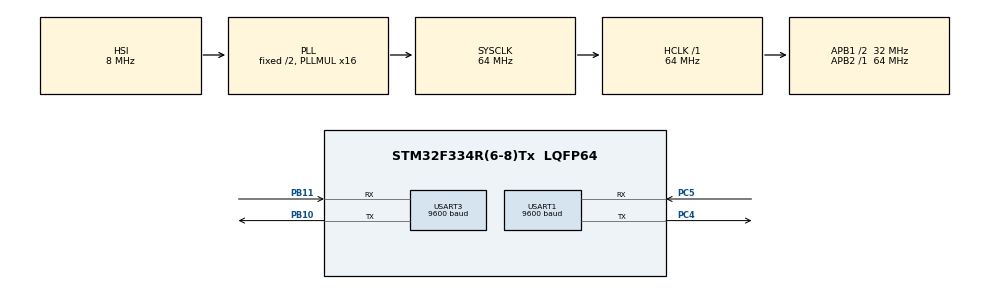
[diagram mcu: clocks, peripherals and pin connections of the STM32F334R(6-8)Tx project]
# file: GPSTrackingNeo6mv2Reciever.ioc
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Mcu.Family=STM32F3
Mcu.Name=STM32F334R(6-8)Tx
Mcu.Package=LQFP64
NVIC.PriorityGroup=NVIC_PRIORITYGROUP_0
NVIC.USART1_IRQn=true\:0\:0\:false\:false\:true\:true\:true\:true
NVIC.USART3_IRQn=true\:0\:0\:false\:false\:true\:true\:true\:true
PA13.Mode=Serial_Wire
PA13.Signal=SYS_JTMS-SWDIO
PA14.Mode=Serial_Wire
PA14.Signal=SYS_JTCK-SWCLK
PB10.Mode=Asynchronous
PB10.Signal=USART3_TX
PB11.Mode=Asynchronous
PB11.Signal=USART3_RX
PC4.Mode=Asynchronous
PC4.Signal=USART1_TX
PC5.Mode=Asynchronous
PC5.Signal=USART1_RX
ProjectManager.HeapSize=0x200
ProjectManager.StackSize=0x400
ProjectManager.TargetToolchain=STM32CubeIDE
RCC.AHBFreq_Value=64000000
RCC.APB1CLKDivider=RCC_HCLK_DIV2
RCC.APB1Freq_Value=32000000
RCC.APB1TimFreq_Value=64000000
RCC.APB2Freq_Value=64000000
RCC.APB2TimFreq_Value=64000000
RCC.CortexFreq_Value=64000000
RCC.FLatency-AdvancedSettings=FLASH_LATENCY_2
RCC.HCLKFreq_Value=64000000
RCC.HSE_VALUE=8000000
RCC.HSI_VALUE=8000000
RCC.PLLMUL=RCC_PLL_MUL16
RCC.SYSCLKFreq_VALUE=64000000
RCC.SYSCLKSourceVirtual=RCC_SYSCLKSOURCE_PLLCLK
USART1.BaudRate=9600
USART1.VirtualMode-Asynchronous=VM_ASYNC
USART3.BaudRate=9600
USART3.VirtualMode-Asynchronous=VM_ASYNC
board=NUCLEO-F334R8

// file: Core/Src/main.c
/* USER CODE BEGIN Header */
/**
  ******************************************************************************
  * @file           : main.c
  * @brief          : Main program body
  ******************************************************************************
  * @attention
  *
  * Copyright (c) 2023 STMicroelectronics.
  * All rights reserved.
  *
  * This software is licensed under terms that can be found in the LICENSE file
  * in the root directory of this software component.
  * If no LICENSE file comes with this software, it is provided AS-IS.
  *
  ******************************************************************************
  */
/* USER CODE END Header */
#include "main.h"

UART_HandleTypeDef huart1;
UART_HandleTypeDef huart3;

/* USER CODE BEGIN PV */

char RxBuffer[24] = { 0 };
char Rxcuffer[1];
int cnt=0;

/* USER CODE END PV */

void SystemClock_Config(void);
static void MX_GPIO_Init(void);
static void MX_USART3_UART_Init(void);
static void MX_USART1_UART_Init(void);

/* USER CODE BEGIN 0 */
void HAL_UART_RxCpltCallback(UART_HandleTypeDef *huart) {

	if (huart->Instance == USART1) {
		//if (Counter_Dma == 0) {
		RxBuffer[cnt++] = Rxcuffer[0];
		if(cnt>23){

			HAL_UART_Transmit(&huart3, RxBuffer,sizeof(RxBuffer), HAL_MAX_DELAY);
			cnt=0;
		}

	}

	HAL_UART_Receive_IT(&huart3, Rxcuffer, 1);

}
/* USER CODE END 0 */

int main(void)
{

  /* MCU Configuration--------------------------------------------------------*/

  /* Reset of all peripherals, Initializes the Flash interface and the Systick. */
  HAL_Init();

  /* Configure the system clock */
  SystemClock_Config();

  /* Initialize all configured peripherals */
  MX_GPIO_Init();
  MX_USART3_UART_Init();
  MX_USART1_UART_Init();

  /* Infinite loop */
  while (1)
  {

  }
}

void SystemClock_Config(void)
{
  RCC_OscInitTypeDef RCC_OscInitStruct = {0};
  RCC_ClkInitTypeDef RCC_ClkInitStruct = {0};
  RCC_PeriphCLKInitTypeDef PeriphClkInit = {0};

  /** Initializes the RCC Oscillators according to the specified parameters
  * in the RCC_OscInitTypeDef structure.
  */
  RCC_OscInitStruct.OscillatorType = RCC_OSCILLATORTYPE_HSI;
  RCC_OscInitStruct.HSIState = RCC_HSI_ON;
  RCC_OscInitStruct.HSICalibrationValue = RCC_HSICALIBRATION_DEFAULT;
  RCC_OscInitStruct.PLL.PLLState = RCC_PLL_ON;
  RCC_OscInitStruct.PLL.PLLSource = RCC_PLLSOURCE_HSI;
  RCC_OscInitStruct.PLL.PLLMUL = RCC_PLL_MUL16;
  if (HAL_RCC_OscConfig(&RCC_OscInitStruct) != HAL_OK)
  {
    Error_Handler();
  }

  /** Initializes the CPU, AHB and APB buses clocks
  */
  RCC_ClkInitStruct.ClockType = RCC_CLOCKTYPE_HCLK|RCC_CLOCKTYPE_SYSCLK
                              |RCC_CLOCKTYPE_PCLK1|RCC_CLOCKTYPE_PCLK2;
  RCC_ClkInitStruct.SYSCLKSource = RCC_SYSCLKSOURCE_PLLCLK;
  RCC_ClkInitStruct.AHBCLKDivider = RCC_SYSCLK_DIV1;
  RCC_ClkInitStruct.APB1CLKDivider = RCC_HCLK_DIV2;
  RCC_ClkInitStruct.APB2CLKDivider = RCC_HCLK_DIV1;

  if (HAL_RCC_ClockConfig(&RCC_ClkInitStruct, FLASH_LATENCY_2) != HAL_OK)
  {
    Error_Handler();
  }
  PeriphClkInit.PeriphClockSelection = RCC_PERIPHCLK_USART1;
  PeriphClkInit.Usart1ClockSelection = RCC_USART1CLKSOURCE_PCLK1;
  if (HAL_RCCEx_PeriphCLKConfig(&PeriphClkInit) != HAL_OK)
  {
    Error_Handler();
  }
}

static void MX_USART1_UART_Init(void)
{

  huart1.Instance = USART1;
  huart1.Init.BaudRate = 9600;
  huart1.Init.WordLength = UART_WORDLENGTH_8B;
  huart1.Init.StopBits = UART_STOPBITS_1;
  huart1.Init.Parity = UART_PARITY_NONE;
  huart1.Init.Mode = UART_MODE_TX_RX;
  huart1.Init.HwFlowCtl = UART_HWCONTROL_NONE;
  huart1.Init.OverSampling = UART_OVERSAMPLING_16;
  huart1.Init.OneBitSampling = UART_ONE_BIT_SAMPLE_DISABLE;
  huart1.AdvancedInit.AdvFeatureInit = UART_ADVFEATURE_NO_INIT;
  if (HAL_UART_Init(&huart1) != HAL_OK)
  {
    Error_Handler();
  }

}

static void MX_USART3_UART_Init(void)
{

  huart3.Instance = USART3;
  huart3.Init.BaudRate = 9600;
  huart3.Init.WordLength = UART_WORDLENGTH_8B;
  huart3.Init.StopBits = UART_STOPBITS_1;
  huart3.Init.Parity = UART_PARITY_NONE;
  huart3.Init.Mode = UART_MODE_TX_RX;
  huart3.Init.HwFlowCtl = UART_HWCONTROL_NONE;
  huart3.Init.OverSampling = UART_OVERSAMPLING_16;
  huart3.Init.OneBitSampling = UART_ONE_BIT_SAMPLE_DISABLE;
  huart3.AdvancedInit.AdvFeatureInit = UART_ADVFEATURE_NO_INIT;
  if (HAL_UART_Init(&huart3) != HAL_OK)
  {
    Error_Handler();
  }

}

static void MX_GPIO_Init(void)
{

  /* GPIO Ports Clock Enable */
  __HAL_RCC_GPIOC_CLK_ENABLE();
  __HAL_RCC_GPIOB_CLK_ENABLE();
  __HAL_RCC_GPIOA_CLK_ENABLE();

}

void Error_Handler(void)
{
  __disable_irq();
  while (1)
  {
  }
}
